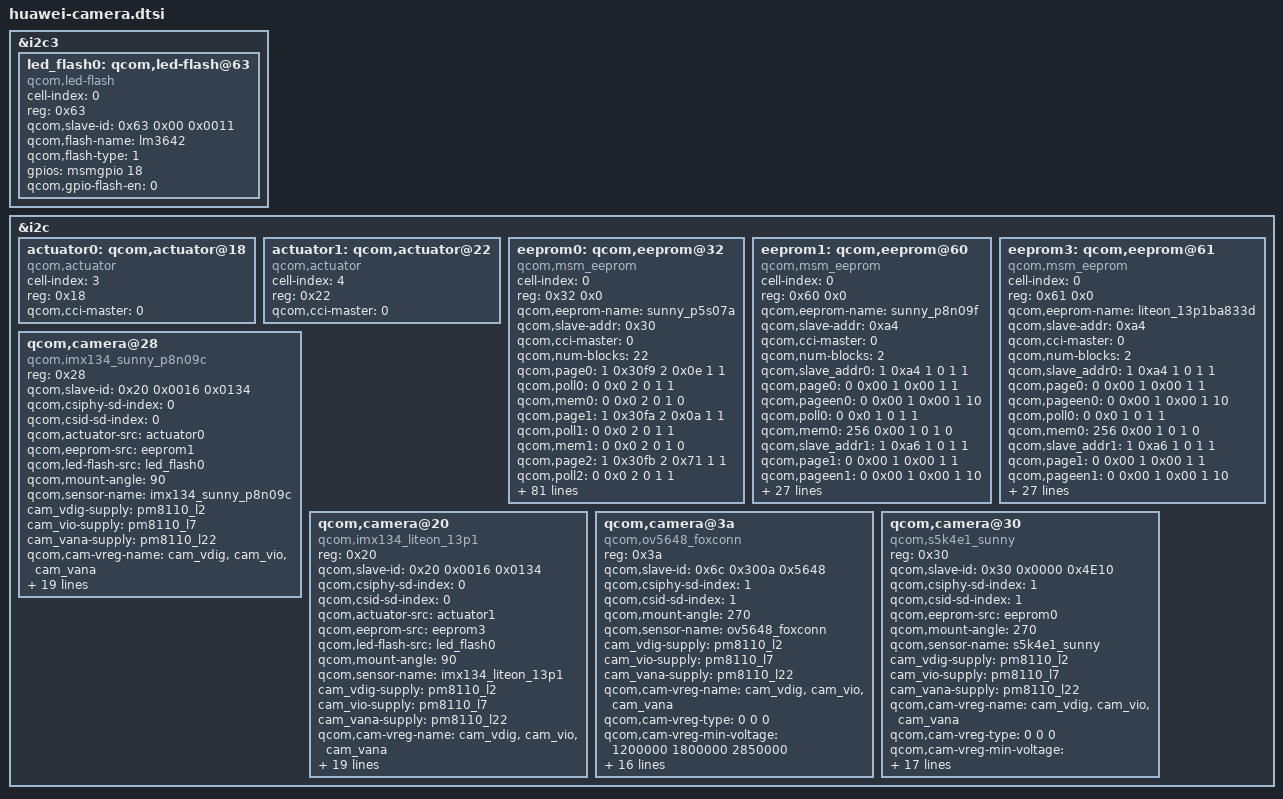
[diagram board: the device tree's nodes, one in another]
/*
 * Copyright (c) 2012-2013, The Linux Foundation. All rights reserved.
 *
 * This program is free software; you can redistribute it and/or modify
 * it under the terms of the GNU General Public License version 2 and
 * only version 2 as published by the Free Software Foundation.
 *
 * This program is distributed in the hope that it will be useful,
 * but WITHOUT ANY WARRANTY; without even the implied warranty of
 * MERCHANTABILITY or FITNESS FOR A PARTICULAR PURPOSE.  See the
 * GNU General Public License for more details.
 */
&i2c3 {
       led_flash0: qcom,led-flash@63 {
                cell-index = <0>;
                reg = <0x63>;
                qcom,slave-id = <0x63 0x00 0x0011>;
                compatible = "qcom,led-flash";
                qcom,flash-name = "lm3642";
                qcom,flash-type = <1>;
                gpios = <&msmgpio 18 0>;
                qcom,gpio-flash-en = <0>;
       };
};

&i2c {
        
	
		actuator0: qcom,actuator@18 {
			cell-index = <3>;
			reg = <0x18>;
			compatible = "qcom,actuator";
			qcom,cci-master = <0>;
		};
		actuator1: qcom,actuator@22 {
			cell-index = <4>;
			reg = <0x22>;
			compatible = "qcom,actuator";
			qcom,cci-master = <0>;
		};	
	
		eeprom0: qcom,eeprom@32{
			cell-index = <0>;
			reg = <0x32 0x0>;
			qcom,eeprom-name = "sunny_p5s07a";
			compatible = "qcom,msm_eeprom";
			qcom,slave-addr = <0x30>;
			qcom,cci-master = <0>;
			qcom,num-blocks = <22>;

			qcom,page0 = <1 0x30f9 2 0x0e 1 1>;
			qcom,poll0 = <0 0x0 2 0 1 1>;
			qcom,mem0 = <0 0x0 2 0 1 0>;
			qcom,page1 = <1 0x30fa 2 0x0a 1 1>;
			qcom,poll1 = <0 0x0 2 0 1 1>;
			qcom,mem1 = <0 0x0 2 0 1 0>;
			qcom,page2 = <1 0x30fb 2 0x71 1 1>;
			qcom,poll2 = <0 0x0 2 0 1 1>;
			qcom,mem2 = <0 0x0 2 0 1 0>;
			qcom,page3 = <1 0x30fb 2 0x70 1 5>;
			qcom,poll3 = <0 0x0 2 0 1 1>;
			qcom,mem3 = <0 0x0 2 0 1 0>;
		
			qcom,page4 = <1 0x310c 2 0x12 1 1>;
			qcom,poll4 = <0 0x0 2 0 1 1>;
			qcom,mem4 = <3 0x310d 2 0 1 0>;
			qcom,page5 = <1 0x310c 2 0x13 1 1>;
			qcom,poll5 = <0 0x0 2 0 1 1>;
			qcom,mem5 = <3 0x310d 2 0 1 0>;
			qcom,page6 = <1 0x310c 2 0x14 1 1>;
			qcom,poll6 = <0 0x0 2 0 1 1>;
			qcom,mem6 = <3 0x310d 2 0 1 0>;		
			qcom,page7 = <1 0x310c 2 0x15 1 1>;
			qcom,poll7 = <0 0x0 2 0 1 1>;
			qcom,mem7 = <3 0x310d 2 0 1 0>;
			qcom,page8 = <1 0x310c 2 0x16 1 1>;
			qcom,poll8 = <0 0x0 2 0 1 1>;
			qcom,mem8 = <3 0x310d 2 0 1 0>;
			qcom,page9 = <1 0x310c 2 0x17 1 1>;
			qcom,poll9 = <0 0x0 2 0 1 1>;
			qcom,mem9 = <3 0x310d 2 0 1 0>;
			qcom,page10 = <1 0x310c 2 0x18 1 1>;
			qcom,poll10 = <0 0x0 2 0 1 1>;
			qcom,mem10 = <3 0x310d 2 0 1 0>;
			qcom,page11 = <1 0x310c 2 0x19 1 1>;
			qcom,poll11 = <0 0x0 2 0 1 1>;
			qcom,mem11 = <3 0x310d 2 0 1 0>;
			qcom,page12 = <1 0x310c 2 0x1a 1 1>;
			qcom,poll12 = <0 0x0 2 0 1 1>;
			qcom,mem12 = <3 0x310d 2 0 1 0>;		
			qcom,page13 = <1 0x310c 2 0x1b 1 1>;
			qcom,poll13 = <0 0x0 2 0 1 1>;
			qcom,mem13 = <3 0x310d 2 0 1 0>;		
			qcom,page14 = <1 0x310c 2 0x1c 1 1>;
			qcom,poll14 = <0 0x0 2 0 1 1>;
			qcom,mem14 = <3 0x310d 2 0 1 0>;		
			qcom,page15 = <1 0x310c 2 0x1d 1 1>;
			qcom,poll15 = <0 0x0 2 0 1 1>;
			qcom,mem15 = <3 0x310d 2 0 1 0>;		
			qcom,page16 = <1 0x310c 2 0x1e 1 1>;
			qcom,poll16 = <0 0x0 2 0 1 1>;
			qcom,mem16 = <3 0x310d 2 0 1 0>;		
			qcom,page17 = <1 0x310c 2 0x1f 1 1>;
			qcom,poll17 = <0 0x0 2 0 1 1>;
			qcom,mem17 = <3 0x310d 2 0 1 0>;		
			qcom,page18 = <1 0x310c 2 0x20 1 1>;
			qcom,poll18 = <0 0x0 2 0 1 1>;
			qcom,mem18 = <3 0x310d 2 0 1 0>;		
			qcom,page19 = <1 0x310c 2 0x21 1 1>;
			qcom,poll19 = <0 0x0 2 0 1 1>;
			qcom,mem19 = <3 0x310d 2 0 1 0>;		
			qcom,page20 = <1 0x310c 2 0x22 1 1>;
			qcom,poll20 = <0 0x0 2 0 1 1>;
			qcom,mem20 = <3 0x310d 2 0 1 0>;			
			qcom,page21 = <1 0x310c 2 0x23 1 1>;
			qcom,poll21 = <0 0x0 2 0 1 1>;
			qcom,mem21 = <3 0x310d 2 0 1 0>;																									

			cam_vdig-supply = <&pm8110_l2>;
			cam_vio-supply = <&pm8110_l7>;
			cam_vana-supply = <&pm8110_l22>;
			qcom,cam-vreg-name = "cam_vdig", "cam_vio", "cam_vana";
			qcom,cam-vreg-type = <0 0 0>;
			qcom,cam-vreg-min-voltage = <0 1800000 2850000>;
			qcom,cam-vreg-max-voltage = <0 1800000 2850000>;
			qcom,cam-vreg-op-mode = <0 200000 100000>;
			qcom,gpio-no-mux = <0>;
			gpios = <&msmgpio 13 0>,
				<&msmgpio 15 0>,
				<&msmgpio 85 0>;
			qcom,gpio-reset = <1>;
			qcom,gpio-standby = <2>;
			qcom,gpio-req-tbl-num = <0 1 2>;
			qcom,gpio-req-tbl-flags = <1 0 0>;
			qcom,gpio-req-tbl-label = "CAMIF_MCLK",
						  "CAM_RESET",
						  "CAM_STANDBY";
			qcom,cam-power-seq-type = "sensor_vreg",
				"sensor_vreg",  "sensor_gpio",
				 "sensor_clk";
			qcom,cam-power-seq-val = "cam_vio", "cam_vana",
				 "sensor_gpio_reset",
				"sensor_cam_mclk" ;
			qcom,cam-power-seq-cfg-val = <1 1 1 24000000>;
			qcom,cam-power-seq-delay = <1 1 10 5>;
		};

		eeprom1: qcom,eeprom@60 {
			cell-index = <0>;
			reg = <0x60 0x0>;
			qcom,eeprom-name = "sunny_p8n09f";
			compatible = "qcom,msm_eeprom";
			qcom,slave-addr = <0xa4>;
			qcom,cci-master = <0>;
			qcom,num-blocks = <2>;
			qcom,slave_addr0 = <1 0xa4 1 0 1 1>;
			qcom,page0 = <0 0x00 1 0x00 1 1>;
			qcom,pageen0 = <0 0x00 1 0x00 1 10>;
			qcom,poll0 = <0 0x0 1 0 1 1>;
			qcom,mem0 = <256 0x00 1 0 1 0>;

			qcom,slave_addr1 = <1 0xa6 1 0 1 1>;
			qcom,page1 = <0 0x00 1 0x00 1 1>;
			qcom,pageen1 = <0 0x00 1 0x00 1 10>;
			qcom,poll1 = <0 0x0 1 0 1 1>;
			qcom,mem1 = <70 0x00 1 0 1 0>;

			cam_vdig-supply = <&pm8110_l2>;
			cam_vio-supply = <&pm8110_l7>;
			cam_vana-supply = <&pm8110_l22>;
			qcom,cam-vreg-name = "cam_vdig", "cam_vio", "cam_vana";
			qcom,cam-vreg-type = <0 0 0>;
			qcom,cam-vreg-min-voltage = <0 1800000 2850000>;
			qcom,cam-vreg-max-voltage = <0 1800000 2850000>;
			qcom,cam-vreg-op-mode = <0 200000 100000>;
			qcom,gpio-no-mux = <0>;
			gpios = <&msmgpio 13 0>,
				<&msmgpio 21 0>,//reset
				<&msmgpio 20 0>;//stanby
			qcom,gpio-reset = <1>;
			qcom,gpio-standby = <2>;
			qcom,gpio-req-tbl-num = <0 1 2>;
			qcom,gpio-req-tbl-flags = <1 0 0>;
			qcom,gpio-req-tbl-label = "CAMIF_MCLK",
					"CAM_RESET1",
					"CAM_STANDBY";
			qcom,cam-power-seq-type = "sensor_vreg",
					"sensor_vreg", "sensor_gpio",
					"sensor_gpio", "sensor_clk";
			qcom,cam-power-seq-val = "cam_vio", "cam_vana",
					"sensor_gpio_reset",
					"sensor_gpio_standby","sensor_cam_mclk" ;
			qcom,cam-power-seq-cfg-val = <1 1 1 1 24000000>;
			qcom,cam-power-seq-delay = <1 1 10 10 5>;
		};
		eeprom3: qcom,eeprom@61 {
			cell-index = <0>;
			reg = <0x61 0x0>;
			qcom,eeprom-name = "liteon_13p1ba833d";
			compatible = "qcom,msm_eeprom";
			qcom,slave-addr = <0xa4>;
			qcom,cci-master = <0>;
			qcom,num-blocks = <2>;
			qcom,slave_addr0 = <1 0xa4 1 0 1 1>;
			qcom,page0 = <0 0x00 1 0x00 1 1>;
			qcom,pageen0 = <0 0x00 1 0x00 1 10>;
			qcom,poll0 = <0 0x0 1 0 1 1>;
			qcom,mem0 = <256 0x00 1 0 1 0>;

			qcom,slave_addr1 = <1 0xa6 1 0 1 1>;
			qcom,page1 = <0 0x00 1 0x00 1 1>;
			qcom,pageen1 = <0 0x00 1 0x00 1 10>;
			qcom,poll1 = <0 0x0 1 0 1 1>;
			qcom,mem1 = <70 0x00 1 0 1 0>;

			cam_vdig-supply = <&pm8110_l2>;
			cam_vio-supply = <&pm8110_l7>;
			cam_vana-supply = <&pm8110_l22>;
			qcom,cam-vreg-name = "cam_vdig", "cam_vio", "cam_vana";
			qcom,cam-vreg-type = <0 0 0>;
			qcom,cam-vreg-min-voltage = <0 1800000 2850000>;
			qcom,cam-vreg-max-voltage = <0 1800000 2850000>;
			qcom,cam-vreg-op-mode = <0 200000 100000>;
			qcom,gpio-no-mux = <0>;
			gpios = <&msmgpio 13 0>,
				<&msmgpio 21 0>,//reset
				<&msmgpio 20 0>;//stanby
			qcom,gpio-reset = <1>;
			qcom,gpio-standby = <2>;
			qcom,gpio-req-tbl-num = <0 1 2>;
			qcom,gpio-req-tbl-flags = <1 0 0>;
			qcom,gpio-req-tbl-label = "CAMIF_MCLK",
					"CAM_RESET1",
					"CAM_STANDBY";
			qcom,cam-power-seq-type = "sensor_vreg",
					"sensor_vreg", "sensor_gpio",
					"sensor_gpio", "sensor_clk";
			qcom,cam-power-seq-val = "cam_vio", "cam_vana",
					"sensor_gpio_reset",
					"sensor_gpio_standby","sensor_cam_mclk" ;
			qcom,cam-power-seq-cfg-val = <1 1 1 1 24000000>;
			qcom,cam-power-seq-delay = <1 1 10 10 5>;
		};
		qcom,camera@28 {
				compatible = "qcom,imx134_sunny_p8n09c";
				reg = <0x28>;
				qcom,slave-id = <0x20 0x0016 0x0134>;
				qcom,csiphy-sd-index = <0>;
				qcom,csid-sd-index = <0>;
			  	qcom,actuator-src = <&actuator0>;
				qcom,eeprom-src = <&eeprom1>;
				qcom,led-flash-src = <&led_flash0>;
				qcom,mount-angle = <90>;
				qcom,sensor-name = "imx134_sunny_p8n09c";
				cam_vdig-supply = <&pm8110_l2>;
				cam_vio-supply = <&pm8110_l7>;
				cam_vana-supply = <&pm8110_l22>;
				qcom,cam-vreg-name = "cam_vdig", "cam_vio", "cam_vana";
				qcom,cam-vreg-type = <0 0 0>;
				qcom,cam-vreg-min-voltage = <0 1800000 2850000>;
				qcom,cam-vreg-max-voltage = <0 1800000 2850000>;
				qcom,cam-vreg-op-mode = <0 200000 100000>;
				qcom,gpio-no-mux = <0>;
				gpios = <&msmgpio 13 0>,
					<&msmgpio 21 0>,//reset
					<&msmgpio 101 0>, //dvdd_en
					<&msmgpio 79 0>; //vcm_pwdn
				qcom,gpio-reset = <1>;
				qcom,gpio-vdig = <2>;
				qcom,gpio-af-pwdm = <3>;
				qcom,gpio-req-tbl-num = <0 1 2 3>;
				qcom,gpio-req-tbl-flags = <1 0 0 0>;
				qcom,gpio-req-tbl-label = "CAMIF_MCLK",
					"CAM_RESET1",
					"CAM_DVDDEN",
					"CAM_VCMPWDN";
				qcom,csi-lane-assign = <0xe4>;
				qcom,csi-lane-mask = <0x7>;
				qcom,sensor-position = <0>;
				qcom,sensor-mode = <1>;
				qcom,cci-master = <0>;
			};
		qcom,camera@20 {
				compatible = "qcom,imx134_liteon_13p1";
				reg = <0x20>;
				qcom,slave-id = <0x20 0x0016 0x0134>;
				qcom,csiphy-sd-index = <0>;
				qcom,csid-sd-index = <0>;
				qcom,actuator-src = <&actuator1>;
				qcom,eeprom-src = <&eeprom3>;
				qcom,led-flash-src = <&led_flash0>;
				qcom,mount-angle = <90>;
				qcom,sensor-name = "imx134_liteon_13p1";
				cam_vdig-supply = <&pm8110_l2>;
				cam_vio-supply = <&pm8110_l7>;
				cam_vana-supply = <&pm8110_l22>;
				qcom,cam-vreg-name = "cam_vdig", "cam_vio", "cam_vana";
				qcom,cam-vreg-type = <0 0 0>;
				qcom,cam-vreg-min-voltage = <0 1800000 2850000>;
				qcom,cam-vreg-max-voltage = <0 1800000 2850000>;
				qcom,cam-vreg-op-mode = <0 200000 100000>;
				qcom,gpio-no-mux = <0>;
				gpios = <&msmgpio 13 0>,
					<&msmgpio 21 0>,//reset
					<&msmgpio 101 0>, //dvdd_en
					<&msmgpio 79 0>; //vcm_pwdn
				qcom,gpio-reset = <1>;
				qcom,gpio-vdig = <2>;
				qcom,gpio-af-pwdm = <3>;
				qcom,gpio-req-tbl-num = <0 1 2 3>;
				qcom,gpio-req-tbl-flags = <1 0 0 0>;
				qcom,gpio-req-tbl-label = "CAMIF_MCLK",
					"CAM_RESET1",
					"CAM_DVDDEN",
					"CAM_VCMPWDN";
				qcom,csi-lane-assign = <0xe4>;
				qcom,csi-lane-mask = <0x7>;
				qcom,sensor-position = <0>;
				qcom,sensor-mode = <1>;
				qcom,cci-master = <0>;
			};
		qcom,camera@3a {
				compatible = "qcom,ov5648_foxconn";
		  		reg = <0x3a>;
		  		qcom,slave-id = <0x6c 0x300a 0x5648>;
		  		qcom,csiphy-sd-index = <1>;
		  		qcom,csid-sd-index = <1>;
		  		qcom,mount-angle = <270>;
		  		qcom,sensor-name = "ov5648_foxconn";
		  		cam_vdig-supply = <&pm8110_l2>;
		  		cam_vio-supply = <&pm8110_l7>;
		  		cam_vana-supply = <&pm8110_l22>;
		  		qcom,cam-vreg-name = "cam_vdig", "cam_vio", "cam_vana";
		  		qcom,cam-vreg-type = <0 0 0>;
		  		qcom,cam-vreg-min-voltage = <1200000 1800000 2850000>;
		  		qcom,cam-vreg-max-voltage = <1200000 1800000 2850000>;
		  		qcom,cam-vreg-op-mode = <0 200000 100000>;
		  		qcom,gpio-no-mux = <0>;
		  		gpios = <&msmgpio 13 0>,
		  			<&msmgpio 15 0>,
		  			<&msmgpio 85 0>;
		  		qcom,gpio-reset = <1>;
		  		qcom,gpio-standby = <2>;
		  		qcom,gpio-req-tbl-num = <0 1 2>;
		  		qcom,gpio-req-tbl-flags = <1 0 0>;
		  		qcom,gpio-req-tbl-label = "CAMIF_MCLK",
		  			  "CAM_RESET",
		  			  "CAM_STANDBY";
		  		qcom,csi-lane-assign = <0xe4>;
		  		qcom,csi-lane-mask = <0x3>;
		  		qcom,sensor-position = <1>;
		 		qcom,sensor-mode = <1>;
		  		qcom,cci-master = <0>;
		};
		
		qcom,camera@30 {
			compatible = "qcom,s5k4e1_sunny";
			reg = <0x30>;
			qcom,slave-id = <0x30 0x0000 0x4E10>;
			qcom,csiphy-sd-index = <1>;
			qcom,csid-sd-index = <1>;
			qcom,eeprom-src = <&eeprom0>;
			qcom,mount-angle = <270>;
			qcom,sensor-name = "s5k4e1_sunny";
			cam_vdig-supply = <&pm8110_l2>;
			cam_vio-supply = <&pm8110_l7>;
			cam_vana-supply = <&pm8110_l22>;
			qcom,cam-vreg-name = "cam_vdig", "cam_vio", "cam_vana";
			qcom,cam-vreg-type = <0 0 0>;
			qcom,cam-vreg-min-voltage = <1200000 1800000 2850000>;
			qcom,cam-vreg-max-voltage = <1200000 1800000 2850000>;
			qcom,cam-vreg-op-mode = <200000 200000 100000>;
			qcom,gpio-no-mux = <0>;
			gpios = <&msmgpio 13 0>,
				<&msmgpio 15 0>,
				<&msmgpio 85 0>;
			qcom,gpio-reset = <1>;
			qcom,gpio-standby = <2>;
			qcom,gpio-req-tbl-num = <0 1 2>;
			qcom,gpio-req-tbl-flags = <1 0 0>;
			qcom,gpio-req-tbl-label = "CAMIF_MCLK",
				"CAM_RESET",
				"CAM_STANDBY";
			qcom,csi-lane-assign = <0xe4>;
			qcom,csi-lane-mask = <0x3>;
			qcom,sensor-position = <1>;
			qcom,sensor-mode = <1>;
			qcom,cci-master = <0>;
		};

	
};
